# NSS_0_CFG_CPTS register map
Vendor: Texas Instruments
Peripheral module from a debugger description file (folder 66AK2G0x_66AK2G1x).
Registers are 32-bit, access per field, reset 0x0 unless marked. A register's access mark holds for its fields unless they carry their own. Offsets are as the file gives them; lines under a group give offsets from that group; [hi:lo] are bit positions; {n}, {i} and the like mark numbered series; 'fields as' and 'values as' point back to an identical list; <NAME> marks a mode.

## NSS_0_CFG_CPTS
0x00 CPTS_IDVER ro reset 0x4E8A0107
  [31:0] REV — TI internal data. Identifies revision of peripheral.
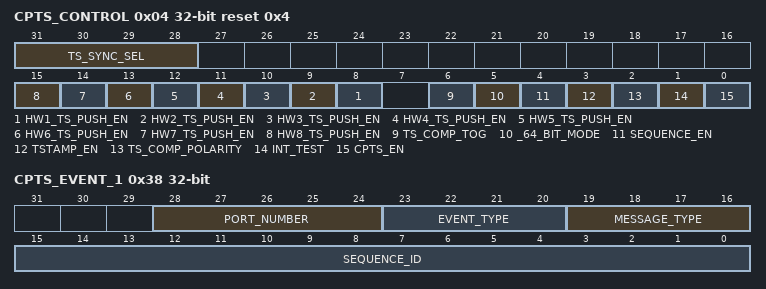
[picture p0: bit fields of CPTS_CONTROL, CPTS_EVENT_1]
0x04 CPTS_CONTROL reset 0x4
  [31:28] TS_SYNC_SEL rw — TS_SYNC output timestamp counter bit select
  [n+7] HW{n}_TS_PUSH_EN rw (n=1..8) — Hardware push {n} enable
  [6] TS_COMP_TOG rw — Timestamp Compare Toggle mode
  [5] _64_BIT_MODE rw
  [4] SEQUENCE_EN rw — Sequence Enable
  [3] TSTAMP_EN rw — Host Receive Timestamp Enable
  [2] TS_COMP_POLARITY rw
  [1] INT_TEST rw — Interrupt test - When set, this bit allows the raw interrupt to be written to facilitate interrupt test.
  [0] CPTS_EN rw — Time sync enable – When disabled (cleared to zero), the RCLK domain is held in reset.
0x08 CPTS_RFTCLK_SEL
  [4:0] RFTCLK_SEL rw — Reference clock select: This RFTCLK_SEL value can be written only when the CPTS_EN bit and the TSTAMP_EN bit are cleared to zero in the
0x0C CPTS_TS_PUSH
  [0] TS_PUSH wo — Time stamp event push – When a logic high is written to this bit a time stamp event is pushed onto the event FIFO. The time stamp value is the time of the write of this register, not the time of the event read. The time stamp value can then be read on interrupt via the event registers. Software should not push a second time stamp event onto the event FIFO until the first time stamp value has been read from the event FIFO (there should be only one time stamp event in the event FIFO at any given time). This bit is write only and always reads zero.
0x10 CPTS_TS_LOAD_LOW_VAL rw
  [31:0] TS_LOAD_VAL — Time stamp load value– Writing the ts_load_en bit causes TS_LOAD_VAL[63:0] to be written into the time stamp. The time stamp value is read by initiating a time stamp push event, not by reading this register. When reading this register, the value read is not the time stamp, but is the value that was last written to this register.
0x14 CPTS_TS_LOAD_EN
  [0] TS_LOAD_EN wo — Time stamp load enable – Writing a one to this bit enables the time stamp value to be written with the value in TS_LOAD_VAL[63:0]. This bit is write only and will be cleared by the hardware after one clock. The upper 32- bits of the timestamp are forced to zero in 32-bit mode.
0x18 CPTS_TS_COMP_LOW_VAL rw
  [31:0] TS_COMP_VAL — Time Stamp Comparison Low Value – Writing a non-zero value to the TS_Comp_Length[15:0] register causes a pulse of TS_Comp_Length RCLK periods on the TS_COMP output and a comparison event when the time_stamp counter value is equivalent to ts_comp_val.
0x1C CPTS_TS_COMP_LEN
  [23:0] TS_COMP_LENGTH rw — Time stamp comparison length - Writing a non-zero value to this field enables the time stamp comparison event and output. This value should be zero when the TS_Comp_Low_Val and TS_Comp_High_Val registers are written.
0x20 CPTS_INTSTAT_RAW
  [0] TS_PEND_RAW rw — TS_PEND_RAW int read (before enable). Writable when int_test = 1 A one in this bit indicates that there are one or more events in the event FIFO.
0x24 CPTS_INTSTAT_MASKED ro
  [0] TS_PEND — TS_PEND masked interrupt read (after enable)
0x28 CPTS_INT_ENABLE
  [0] TS_PEND_EN rw — TS_PEND masked interrupt enable.
0x2C CPTS_TS_COMP_NUDGE
  [7:0] TS_COMP_NUDGE rw — Timestamp Comparison Nudge Value. This two’s complement number is added to the ts_comp_length[23:0] value to increase or decrease the TS_COMP length by the ts_comp_nudge amount. Only a single high or low time is adjusted and the ts_comp_nudge value is cleared to zero when the nudge has occurred.
0x30 CPTS_EVENT_POP
  [0] EVENT_POP wo — Event pop - When a logic high is written to this bit an event is popped off the event FIFO. The event FIFO pop occurs as part of the interrupt process after the event has been read from the Event_0-3 registers. Popping an event discards the event and causes the next event, if any, to be moved to the top of the FIFO ready to be read by software on interrupt.
0x34 CPTS_EVENT_0 ro reset not defined
  [31:0] TIME_STAMP — Time Stamp – The timestamp is valid for transmit, receive, and time stamp push event types. The timestamp value is not valid for counter roll event types.
0x38 CPTS_EVENT_1 ro reset not defined
  [28:24] PORT_NUMBER — Port number - indicates the port number (encoded) of an Ethernet event or the encoded hardware timestamp number.
  [23:20] EVENT_TYPE
  [19:16] MESSAGE_TYPE — Message type – The message type value that was contained in an Ethernet transmit or receive time sync packet. This field is valid only for Ethernet transmit or receive events.
  [15:0] SEQUENCE_ID — Sequence ID – The 16-bit sequence id is the value that was contained in an Ethernet transmit or receive time sync packet. This field is valid only for Ethernet transmit or receive events.
0x3C CPTS_EVENT_2 ro reset not defined
  [7:0] DOMAIN — Domain – The 8-bit domain is the value that was contained in an Ethernet transmit or receive time sync packet. This field is valid only for Ethernet transmit or receive events.
0x40 CPTS_EVENT_3 ro reset not defined
  [31:0] TIME_STAMP — Time Stamp – The timestamp upper 32-bits are valid for transmit, receive, and time stamp push event types. This value is zero in 32-bit mode.
0x44 CPTS_TS_LOAD_HIGH_VAL rw
  [31:0] TS_LOAD_VAL — Time Stamp Load high Value – Writing the ts_load_en bit causes the value contained in this register (and the CPTS_TS_LOAD_VAL[63:0]) to be written into the time stamp. The time stamp value is read by initiating a time stamp push event, not by reading this register. When reading this register, the value read is not the time stamp, but is the value that was last written to this register. This value is unused in 32-bit mode
0x48 CPTS_TS_COMP_HIGH_VAL rw
  [31:0] TS_COMP_VAL — Time Stamp Comparison High Value – Writing a non-zero value to the TS_Comp_Length[15:0] register causes a pulse of TS_Comp_Length RCLK periods on the TS_COMP output and a comparison event when the time_stamp counter value is equivalent to ts_comp_val[63:0]. This value is unused in 32-bit mode. The upper 32-bits in this register should be written before the lower 32-bits in the TS_Comp_Low_Val register.
